# ESP32-S3 register map
Vendor: ESPRESSIF SYSTEMS (SHANGHAI) CO., LTD.; Series: ESP32 S-Series; File version: 22
CPU: Xtensa LX7 r0p0, little endian, no MPU, FPU, 0 interrupt priority bits
Address unit: 32 bits
Registers are 32-bit, read-write, reset 0x0 unless marked. A register's access mark holds for its fields unless they carry their own. Offsets are from the block's base; [hi:lo] are bit positions; {n}, {i} and the like mark numbered series.

## SENS — SENS Peripheral
Base 0x60008800
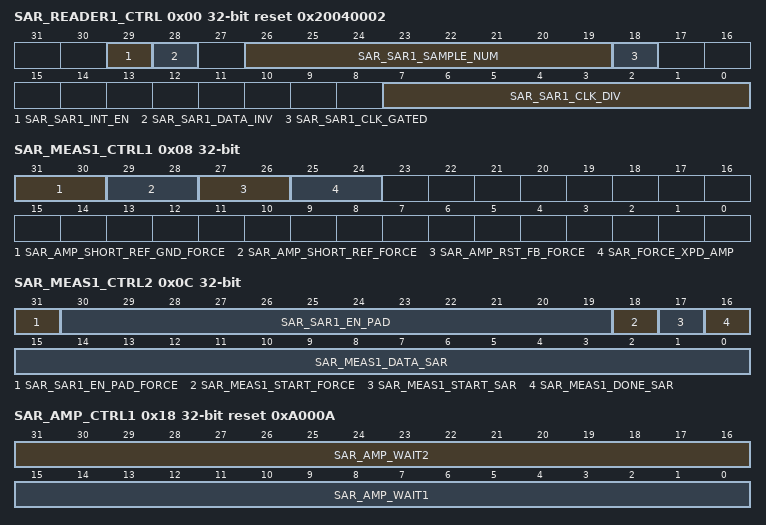
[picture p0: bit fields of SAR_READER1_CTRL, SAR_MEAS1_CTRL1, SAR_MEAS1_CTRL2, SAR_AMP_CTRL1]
0x00 SAR_READER1_CTRL reset 0x20040002 — configure saradc1 reader
  [29] SAR_SAR1_INT_EN — enable saradc1 to send out interrupt
  [28] SAR_SAR1_DATA_INV — Invert SAR ADC1 data
  [26:19] SAR_SAR1_SAMPLE_NUM — no public
  [18] SAR_SAR1_CLK_GATED — no public
  [7:0] SAR_SAR1_CLK_DIV — clock divider
0x04 SAR_READER1_STATUS ro — get saradc1 reader controller status
  [31:0] SAR_SAR1_READER_STATUS
0x08 SAR_MEAS1_CTRL1 — no public
  [31:30] SAR_AMP_SHORT_REF_GND_FORCE — no public
  [29:28] SAR_AMP_SHORT_REF_FORCE — no public
  [27:26] SAR_AMP_RST_FB_FORCE — no public
  [25:24] SAR_FORCE_XPD_AMP — no public
0x0C SAR_MEAS1_CTRL2 access per field — configure saradc1 controller
  [31] SAR_SAR1_EN_PAD_FORCE rw — 1: SAR ADC1 pad enable bitmap is controlled by SW
  [30:19] SAR_SAR1_EN_PAD rw — SAR ADC1 pad enable bitmap
  [18] SAR_MEAS1_START_FORCE rw — 1: SAR ADC1 controller (in RTC) is started by SW
  [17] SAR_MEAS1_START_SAR rw — SAR ADC1 controller (in RTC) starts conversion
  [16] SAR_MEAS1_DONE_SAR ro — SAR ADC1 conversion done indication
  [15:0] SAR_MEAS1_DATA_SAR ro — SAR ADC1 data
0x10 SAR_MEAS1_MUX — configure saradc1 controller
  [31] SAR_SAR1_DIG_FORCE — 1: SAR ADC1 controlled by DIG ADC1 CTRL
0x14 SAR_ATTEN1 reset 0xFFFFFFFF — configure saradc1 controller
  [31:0] SAR_SAR1_ATTEN — 2-bit attenuation for each pad
0x18 SAR_AMP_CTRL1 reset 0xA000A — no public
  [31:16] SAR_AMP_WAIT2 — no public
  [15:0] SAR_AMP_WAIT1 — no public
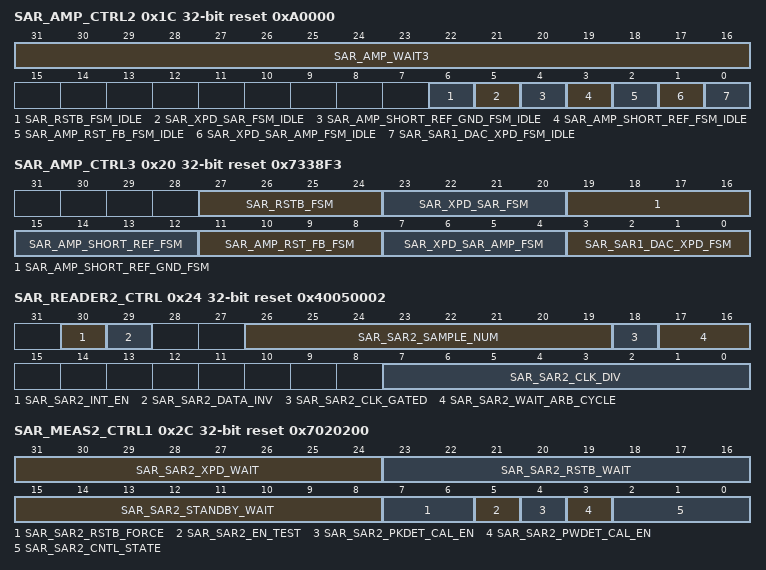
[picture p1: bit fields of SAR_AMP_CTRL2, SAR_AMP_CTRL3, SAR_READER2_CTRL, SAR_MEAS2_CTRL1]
0x1C SAR_AMP_CTRL2 reset 0xA0000 — no public
  [31:16] SAR_AMP_WAIT3 — no public
  [6] SAR_RSTB_FSM_IDLE — no public
  [5] SAR_XPD_SAR_FSM_IDLE — no public
  [4] SAR_AMP_SHORT_REF_GND_FSM_IDLE — no public
  [3] SAR_AMP_SHORT_REF_FSM_IDLE — no public
  [2] SAR_AMP_RST_FB_FSM_IDLE — no public
  [1] SAR_XPD_SAR_AMP_FSM_IDLE — no public
  [0] SAR_SAR1_DAC_XPD_FSM_IDLE — no public
0x20 SAR_AMP_CTRL3 reset 0x7338F3 — no public
  [27:24] SAR_RSTB_FSM — no public
  [23:20] SAR_XPD_SAR_FSM — no public
  [19:16] SAR_AMP_SHORT_REF_GND_FSM — no public
  [15:12] SAR_AMP_SHORT_REF_FSM — no public
  [11:8] SAR_AMP_RST_FB_FSM — no public
  [7:4] SAR_XPD_SAR_AMP_FSM — no public
  [3:0] SAR_SAR1_DAC_XPD_FSM — no public
0x24 SAR_READER2_CTRL reset 0x40050002 — configure saradc2 reader
  [30] SAR_SAR2_INT_EN — enable saradc2 to send out interrupt
  [29] SAR_SAR2_DATA_INV — Invert SAR ADC2 data
  [26:19] SAR_SAR2_SAMPLE_NUM — ******* Description ***********
  [18] SAR_SAR2_CLK_GATED — ******* Description ***********
  [17:16] SAR_SAR2_WAIT_ARB_CYCLE — wait arbit stable after sar_done
  [7:0] SAR_SAR2_CLK_DIV — clock divider
0x28 SAR_READER2_STATUS ro — get saradc1 reader controller status
  [31:0] SAR_SAR2_READER_STATUS
0x2C SAR_MEAS2_CTRL1 access per field reset 0x7020200 — configure saradc2 controller
  [31:24] SAR_SAR2_XPD_WAIT rw — no public
  [23:16] SAR_SAR2_RSTB_WAIT rw — no public
  [15:8] SAR_SAR2_STANDBY_WAIT rw — no public
  [7:6] SAR_SAR2_RSTB_FORCE rw — no public
  [5] SAR_SAR2_EN_TEST rw — SAR2_EN_TEST
  [4] SAR_SAR2_PKDET_CAL_EN rw — rtc control pkdet enable
  [3] SAR_SAR2_PWDET_CAL_EN rw — rtc control pwdet enable
  [2:0] SAR_SAR2_CNTL_STATE ro — saradc2_cntl_fsm
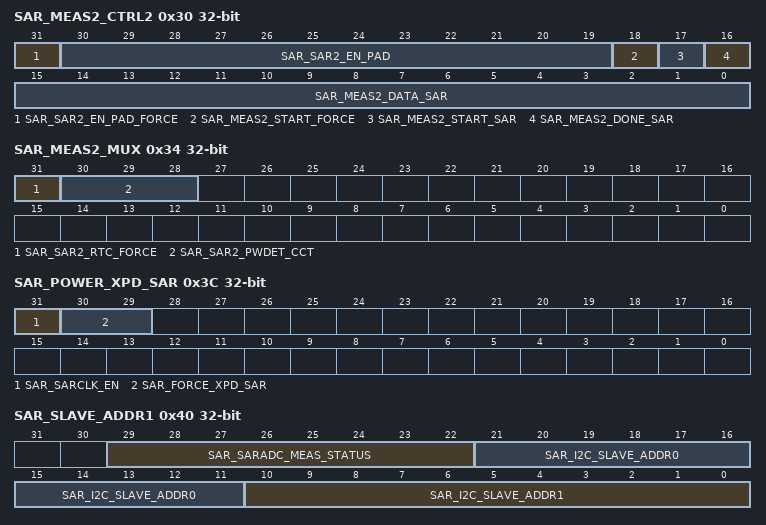
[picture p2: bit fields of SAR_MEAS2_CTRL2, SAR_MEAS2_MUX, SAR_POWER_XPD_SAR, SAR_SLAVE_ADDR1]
0x30 SAR_MEAS2_CTRL2 access per field — configure saradc2 controller
  [31] SAR_SAR2_EN_PAD_FORCE rw — 1: SAR ADC2 pad enable bitmap is controlled by SW
  [30:19] SAR_SAR2_EN_PAD rw — SAR ADC2 pad enable bitmap
  [18] SAR_MEAS2_START_FORCE rw — 1: SAR ADC2 controller (in RTC) is started by SW
  [17] SAR_MEAS2_START_SAR rw — SAR ADC2 controller (in RTC) starts conversion
  [16] SAR_MEAS2_DONE_SAR ro — SAR ADC2 conversion done indication
  [15:0] SAR_MEAS2_DATA_SAR ro — SAR ADC2 data
0x34 SAR_MEAS2_MUX — configure saradc2 controller
  [31] SAR_SAR2_RTC_FORCE — in sleep, force to use rtc to control ADC
  [30:28] SAR_SAR2_PWDET_CCT — SAR2_PWDET_CCT
0x38 SAR_ATTEN2 reset 0xFFFFFFFF — configure saradc2 controller
  [31:0] SAR_SAR2_ATTEN — 2-bit attenuation for each pad
0x3C SAR_POWER_XPD_SAR — configure power of saradc
  [31] SAR_SARCLK_EN — no public
  [30:29] SAR_FORCE_XPD_SAR — force power on/off saradc
0x40 SAR_SLAVE_ADDR1 access per field — configure i2c slave address
  [29:22] SAR_SARADC_MEAS_STATUS ro — no public
  [21:11] SAR_I2C_SLAVE_ADDR0 rw — configure i2c slave address0
  [10:0] SAR_I2C_SLAVE_ADDR1 rw — configure i2c slave address1
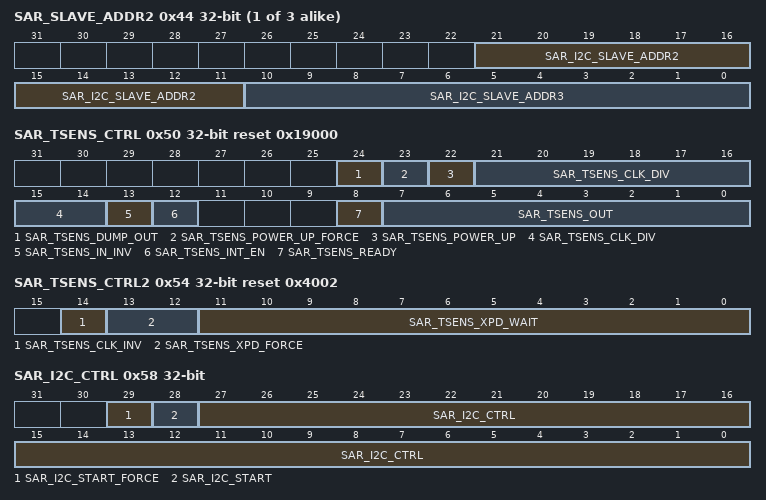
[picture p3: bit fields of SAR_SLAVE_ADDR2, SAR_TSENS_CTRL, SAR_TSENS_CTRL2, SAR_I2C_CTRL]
{0x3C+4i} SAR_SLAVE_ADDR{i} (i=2..4) — configure i2c slave address
  [21:11] SAR_I2C_SLAVE_ADDR{2i-2} — configure i2c slave address{2i-2}
  [10:0] SAR_I2C_SLAVE_ADDR{2i-1} — configure i2c slave address{2i-1}
0x50 SAR_TSENS_CTRL access per field reset 0x19000 — configure tsens controller
  [24] SAR_TSENS_DUMP_OUT rw — temperature sensor dump out only active when reg_tsens_power_up_force = 1
  [23] SAR_TSENS_POWER_UP_FORCE rw — 1: dump out & power up controlled by SW 0: by FSM
  [22] SAR_TSENS_POWER_UP rw — temperature sensor power up
  [21:14] SAR_TSENS_CLK_DIV rw — temperature sensor clock divider
  [13] SAR_TSENS_IN_INV rw — invert temperature sensor data
  [12] SAR_TSENS_INT_EN rw — enable temperature sensor to send out interrupt
  [8] SAR_TSENS_READY ro — indicate temperature sensor out ready
  [7:0] SAR_TSENS_OUT ro — temperature sensor data out
0x54 SAR_TSENS_CTRL2 reset 0x4002 — configure tsens controller
  [14] SAR_TSENS_CLK_INV — no public
  [13:12] SAR_TSENS_XPD_FORCE — no public
  [11:0] SAR_TSENS_XPD_WAIT — no public
0x58 SAR_I2C_CTRL — configure rtc i2c controller by sw
  [29] SAR_I2C_START_FORCE — 1: I2C started by SW 0: I2C started by FSM
  [28] SAR_I2C_START — start I2C only active when reg_sar_i2c_start_force = 1
  [27:0] SAR_I2C_CTRL — I2C control data only active when reg_sar_i2c_start_force = 1
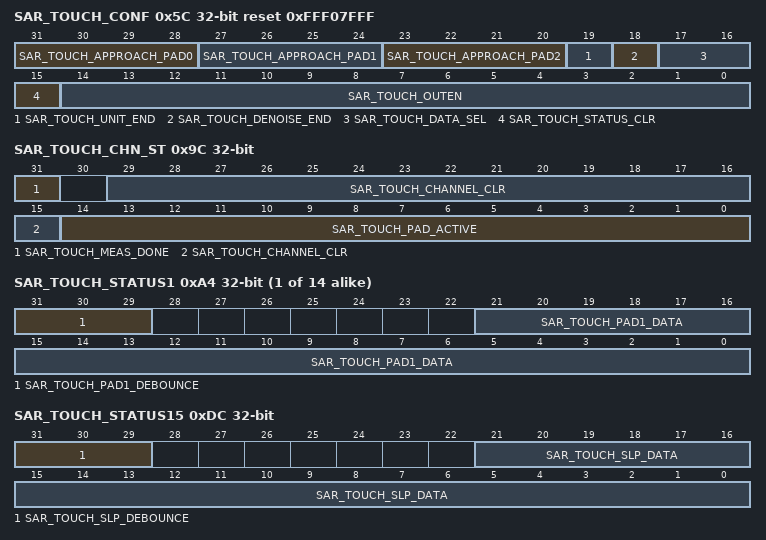
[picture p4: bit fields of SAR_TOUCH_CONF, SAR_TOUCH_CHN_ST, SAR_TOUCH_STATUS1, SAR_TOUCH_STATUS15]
0x5C SAR_TOUCH_CONF access per field reset 0xFFF07FFF — configure touch controller
  [31:28] SAR_TOUCH_APPROACH_PAD0 rw — indicate which pad is approach pad0
  [27:24] SAR_TOUCH_APPROACH_PAD1 rw — indicate which pad is approach pad1
  [23:20] SAR_TOUCH_APPROACH_PAD2 rw — indicate which pad is approach pad2
  [19] SAR_TOUCH_UNIT_END ro — touch_unit_done
  [18] SAR_TOUCH_DENOISE_END ro — touch_denoise_done
  [17:16] SAR_TOUCH_DATA_SEL rw — 3: smooth data 2: baseline 1,0: raw_data
  [15] SAR_TOUCH_STATUS_CLR wo — clear all touch active status
  [14:0] SAR_TOUCH_OUTEN rw — touch controller output enable
0x60 SAR_TOUCH_DENOISE ro — configure touch controller
  [21:0] DATA
{0x60+4i} SAR_TOUCH_THRES{i} (i=1..14) — configure touch thres of touch pad
  [21:0] SAR_TOUCH_OUT_TH{i} — Finger threshold for touch pad {i}
0x9C SAR_TOUCH_CHN_ST access per field — Get touch channel status
  [31] SAR_TOUCH_MEAS_DONE ro — get touch meas done
  [29:15] SAR_TOUCH_CHANNEL_CLR wo — Clear touch channel
  [14:0] SAR_TOUCH_PAD_ACTIVE ro — touch active status
0xA0 SAR_TOUCH_STATUS0 ro — get touch scan status
  [25:22] SAR_TOUCH_SCAN_CURR — current sample channel
{0xA0+4i} SAR_TOUCH_STATUS{i} ro (i=1..14) — touch channel status of touch pad {i}
  [31:29] SAR_TOUCH_PAD{i}_DEBOUNCE — touch current debounce of touch pad {i}
  [21:0] SAR_TOUCH_PAD{i}_DATA — touch data debounce of touch pad {i}
0xDC SAR_TOUCH_STATUS15 ro — touch channel status of sleep pad
  [31:29] SAR_TOUCH_SLP_DEBOUNCE — touch current debounce of sleep pad
  [21:0] SAR_TOUCH_SLP_DATA — touch data debounce of sleep pad
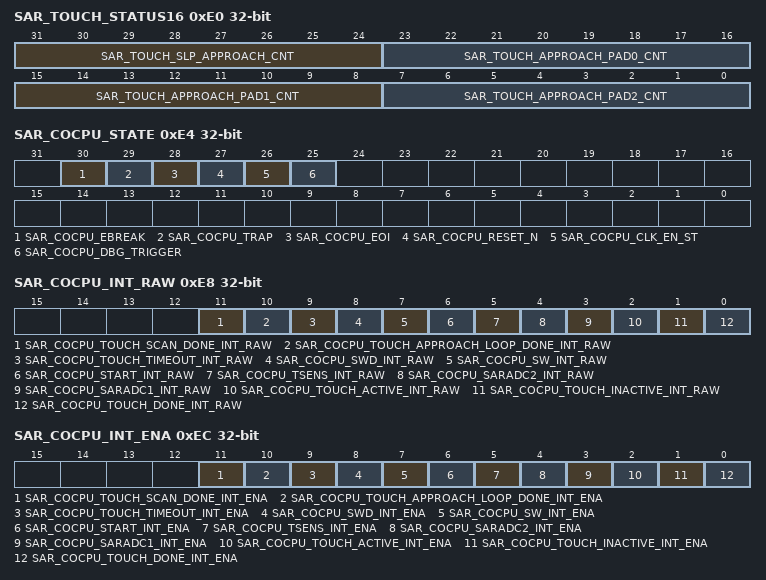
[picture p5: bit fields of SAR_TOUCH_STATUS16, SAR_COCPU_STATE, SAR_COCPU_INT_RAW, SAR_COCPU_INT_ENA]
0xE0 SAR_TOUCH_STATUS16 ro — touch channel status of approach mode
  [31:24] SAR_TOUCH_SLP_APPROACH_CNT — touch current approach count of slp pad
  [23:16] SAR_TOUCH_APPROACH_PAD0_CNT — touch current approach count of approach pad0
  [15:8] SAR_TOUCH_APPROACH_PAD1_CNT — touch current approach count of approach pad1
  [7:0] SAR_TOUCH_APPROACH_PAD2_CNT — touch current approach count of approach pad2
0xE4 SAR_COCPU_STATE access per field — get cocpu status
  [30] SAR_COCPU_EBREAK ro — check cocpu whether in ebreak
  [29] SAR_COCPU_TRAP ro — check cocpu whether in trap state
  [28] SAR_COCPU_EOI ro — check cocpu whether in interrupt state
  [27] SAR_COCPU_RESET_N ro — check cocpu whether in reset state
  [26] SAR_COCPU_CLK_EN_ST ro — check cocpu whether clk on
  [25] SAR_COCPU_DBG_TRIGGER wo — trigger cocpu debug registers
0xE8 SAR_COCPU_INT_RAW ro — the interrupt raw of ulp
  [11] SAR_COCPU_TOUCH_SCAN_DONE_INT_RAW — int from touch scan done
  [10] SAR_COCPU_TOUCH_APPROACH_LOOP_DONE_INT_RAW — int from approach loop done
  [9] SAR_COCPU_TOUCH_TIMEOUT_INT_RAW — int from timeout done
  [8] SAR_COCPU_SWD_INT_RAW — int from super watch dog
  [7] SAR_COCPU_SW_INT_RAW — int from software
  [6] SAR_COCPU_START_INT_RAW — int from start
  [5] SAR_COCPU_TSENS_INT_RAW — int from tsens
  [4] SAR_COCPU_SARADC2_INT_RAW — int from saradc2
  [3] SAR_COCPU_SARADC1_INT_RAW — int from saradc1
  [2] SAR_COCPU_TOUCH_ACTIVE_INT_RAW — int from touch active
  [1] SAR_COCPU_TOUCH_INACTIVE_INT_RAW — int from touch inactive
  [0] SAR_COCPU_TOUCH_DONE_INT_RAW — int from touch done
0xEC SAR_COCPU_INT_ENA — the interrupt enable of ulp
  [11] SAR_COCPU_TOUCH_SCAN_DONE_INT_ENA — int enable of touch scan done
  [10] SAR_COCPU_TOUCH_APPROACH_LOOP_DONE_INT_ENA — int enable of approach loop done
  [9] SAR_COCPU_TOUCH_TIMEOUT_INT_ENA — int enable of timeout done
  [8] SAR_COCPU_SWD_INT_ENA — int enable of super watch dog
  [7] SAR_COCPU_SW_INT_ENA — int enable of software
  [6] SAR_COCPU_START_INT_ENA — int enable of start
  [5] SAR_COCPU_TSENS_INT_ENA — int enable of tsens
  [4] SAR_COCPU_SARADC2_INT_ENA — int enable of from saradc2
  [3] SAR_COCPU_SARADC1_INT_ENA — int enable of from saradc1
  [2] SAR_COCPU_TOUCH_ACTIVE_INT_ENA — int enable of touch active
  [1] SAR_COCPU_TOUCH_INACTIVE_INT_ENA — int enable of from touch inactive
  [0] SAR_COCPU_TOUCH_DONE_INT_ENA — int enable of touch done
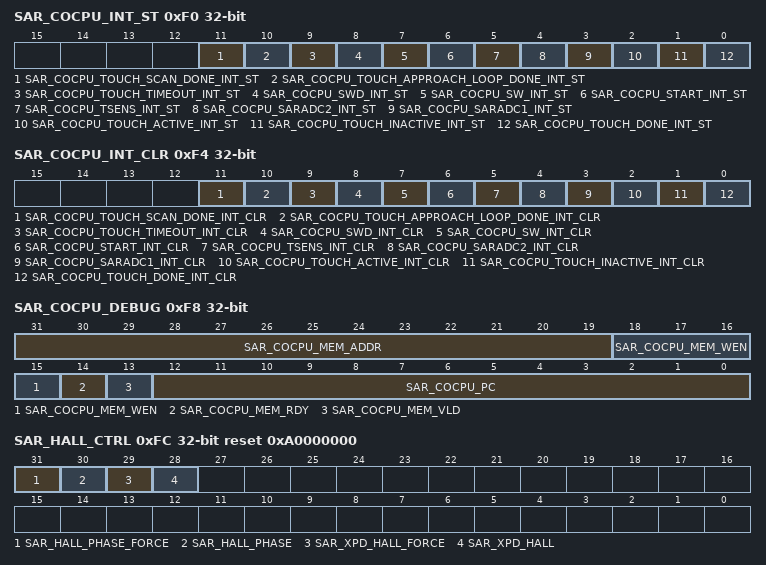
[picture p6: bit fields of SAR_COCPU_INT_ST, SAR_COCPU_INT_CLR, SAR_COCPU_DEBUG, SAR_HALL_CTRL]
0xF0 SAR_COCPU_INT_ST ro — the interrupt state of ulp
  [11] SAR_COCPU_TOUCH_SCAN_DONE_INT_ST — int state of touch scan done
  [10] SAR_COCPU_TOUCH_APPROACH_LOOP_DONE_INT_ST — int state of approach loop done
  [9] SAR_COCPU_TOUCH_TIMEOUT_INT_ST — int state of timeout done
  [8] SAR_COCPU_SWD_INT_ST — int state of super watch dog
  [7] SAR_COCPU_SW_INT_ST — int state of software
  [6] SAR_COCPU_START_INT_ST — int state of start
  [5] SAR_COCPU_TSENS_INT_ST — int state of tsens
  [4] SAR_COCPU_SARADC2_INT_ST — int state of from saradc2
  [3] SAR_COCPU_SARADC1_INT_ST — int state of from saradc1
  [2] SAR_COCPU_TOUCH_ACTIVE_INT_ST — int state of touch active
  [1] SAR_COCPU_TOUCH_INACTIVE_INT_ST — int state of from touch inactive
  [0] SAR_COCPU_TOUCH_DONE_INT_ST — int state of touch done
0xF4 SAR_COCPU_INT_CLR wo — the interrupt clear of ulp
  [11] SAR_COCPU_TOUCH_SCAN_DONE_INT_CLR — int clear of touch scan done
  [10] SAR_COCPU_TOUCH_APPROACH_LOOP_DONE_INT_CLR — int clear of approach loop done
  [9] SAR_COCPU_TOUCH_TIMEOUT_INT_CLR — int clear of timeout done
  [8] SAR_COCPU_SWD_INT_CLR — int clear of super watch dog
  [7] SAR_COCPU_SW_INT_CLR — int clear of software
  [6] SAR_COCPU_START_INT_CLR — int clear of start
  [5] SAR_COCPU_TSENS_INT_CLR — int clear of tsens
  [4] SAR_COCPU_SARADC2_INT_CLR — int clear of from saradc2
  [3] SAR_COCPU_SARADC1_INT_CLR — int clear of from saradc1
  [2] SAR_COCPU_TOUCH_ACTIVE_INT_CLR — int clear of touch active
  [1] SAR_COCPU_TOUCH_INACTIVE_INT_CLR — int clear of from touch inactive
  [0] SAR_COCPU_TOUCH_DONE_INT_CLR — int clear of touch done
0xF8 SAR_COCPU_DEBUG ro — Ulp-riscv debug signal
  [31:19] SAR_COCPU_MEM_ADDR — cocpu mem address output
  [18:15] SAR_COCPU_MEM_WEN — cocpu mem write enable output
  [14] SAR_COCPU_MEM_RDY — cocpu mem ready input
  [13] SAR_COCPU_MEM_VLD — cocpu mem valid output
  [12:0] SAR_COCPU_PC — cocpu Program counter
0xFC SAR_HALL_CTRL reset 0xA0000000 — no public
  [31] SAR_HALL_PHASE_FORCE — 1: HALL PHASE is controlled by SW 0: HALL PHASE is controlled by FSM in ULP-coprocessor
  [30] SAR_HALL_PHASE — Reverse phase of hall sensor
  [29] SAR_XPD_HALL_FORCE — 1: XPD HALL is controlled by SW. 0: XPD HALL is controlled by FSM in ULP-coprocessor
  [28] SAR_XPD_HALL — Power on hall sensor and connect to VP and VN
0x100 SAR_NOUSE — no public
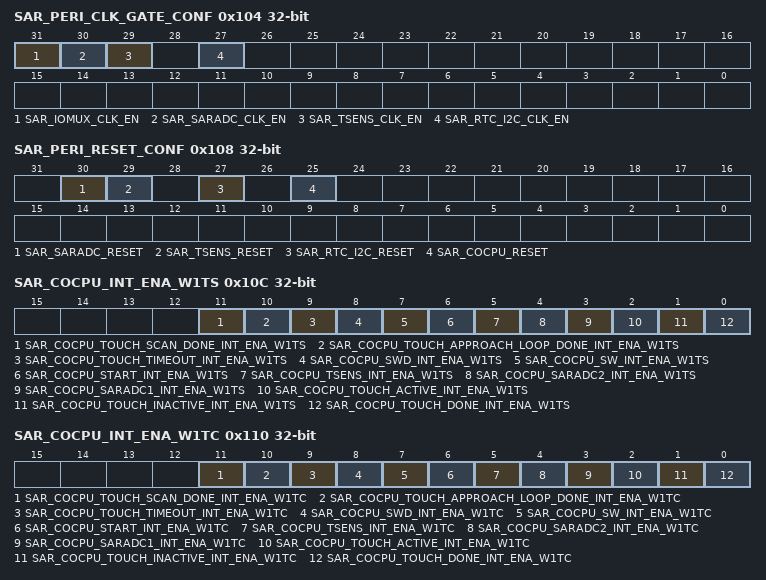
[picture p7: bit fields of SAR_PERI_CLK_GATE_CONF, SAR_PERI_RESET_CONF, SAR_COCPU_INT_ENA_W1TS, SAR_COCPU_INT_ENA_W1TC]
0x104 SAR_PERI_CLK_GATE_CONF — the peri clock gate of rtc peri
  [31] SAR_IOMUX_CLK_EN — enable io_mux clock
  [30] SAR_SARADC_CLK_EN — enbale saradc clock
  [29] SAR_TSENS_CLK_EN — enable tsens clock
  [27] SAR_RTC_I2C_CLK_EN — enable rtc i2c clock
0x108 SAR_PERI_RESET_CONF — the peri reset of rtc peri
  [30] SAR_SARADC_RESET — enable io_mux reset
  [29] SAR_TSENS_RESET — enbale saradc reset
  [27] SAR_RTC_I2C_RESET — Reserved.
  [25] SAR_COCPU_RESET — enable ulp-riscv reset
0x10C SAR_COCPU_INT_ENA_W1TS wo — the interrupt enable of ulp
  [11] SAR_COCPU_TOUCH_SCAN_DONE_INT_ENA_W1TS — int enable of touch scan done
  [10] SAR_COCPU_TOUCH_APPROACH_LOOP_DONE_INT_ENA_W1TS — int enable of approach loop done
  [9] SAR_COCPU_TOUCH_TIMEOUT_INT_ENA_W1TS — int enable of timeout done
  [8] SAR_COCPU_SWD_INT_ENA_W1TS — int enable of super watch dog
  [7] SAR_COCPU_SW_INT_ENA_W1TS — int enable of software
  [6] SAR_COCPU_START_INT_ENA_W1TS — int enable of start
  [5] SAR_COCPU_TSENS_INT_ENA_W1TS — int enable of tsens
  [4] SAR_COCPU_SARADC2_INT_ENA_W1TS — int enable of from saradc2
  [3] SAR_COCPU_SARADC1_INT_ENA_W1TS — int enable of from saradc1
  [2] SAR_COCPU_TOUCH_ACTIVE_INT_ENA_W1TS — int enable of touch active
  [1] SAR_COCPU_TOUCH_INACTIVE_INT_ENA_W1TS — int enable of from touch inactive
  [0] SAR_COCPU_TOUCH_DONE_INT_ENA_W1TS — int enable of touch done
0x110 SAR_COCPU_INT_ENA_W1TC wo — the interrupt enable clear of ulp
  [11] SAR_COCPU_TOUCH_SCAN_DONE_INT_ENA_W1TC — Clear int enable of touch scan done
  [10] SAR_COCPU_TOUCH_APPROACH_LOOP_DONE_INT_ENA_W1TC — Clear int enable of approach loop done
  [9] SAR_COCPU_TOUCH_TIMEOUT_INT_ENA_W1TC — Clear int enable of timeout done
  [8] SAR_COCPU_SWD_INT_ENA_W1TC — Clear int enable of super watch dog
  [7] SAR_COCPU_SW_INT_ENA_W1TC — Clear int enable of software
  [6] SAR_COCPU_START_INT_ENA_W1TC — Clear int enable of start
  [5] SAR_COCPU_TSENS_INT_ENA_W1TC — Clear int enable of tsens
  [4] SAR_COCPU_SARADC2_INT_ENA_W1TC — Clear int enable of from saradc2
  [3] SAR_COCPU_SARADC1_INT_ENA_W1TC — Clear int enable of from saradc1
  [2] SAR_COCPU_TOUCH_ACTIVE_INT_ENA_W1TC — Clear int enable of touch active
  [1] SAR_COCPU_TOUCH_INACTIVE_INT_ENA_W1TC — Clear int enable of from touch inactive
  [0] SAR_COCPU_TOUCH_DONE_INT_ENA_W1TC — Clear int enable of touch done
0x114 SAR_DEBUG_CONF — rtc peri debug configure
  [4:0] SAR_DEBUG_BIT_SEL — no public
0x1FC SAR_SARDATE reset 0x2101180 — version
  [27:0] SAR_DATE
